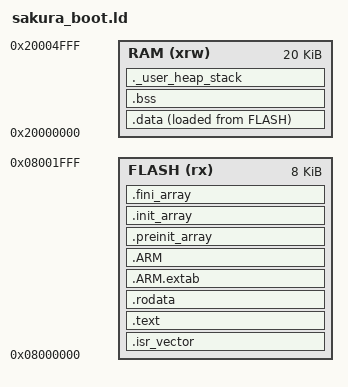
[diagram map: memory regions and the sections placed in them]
/*
 * Linker script for sakura_boot CAN bootloader
 * STM32F103CBTx (FCM32 clone) — 128KB FLASH, 20KB RAM
 *
 * Memory map:
 *   0x08000000 - 0x08001FFF  Bootloader (8KB)
 *   0x08002000 - 0x080023FF  Metadata page (1KB)  — written by host during flash
 *   0x08002400 - 0x0800FBFF  Application (54KB)
 *   0x0800FC00 - 0x0800FFFF  NVS (1KB)
 */

ENTRY(Reset_Handler)

MEMORY
{
  RAM (xrw)    : ORIGIN = 0x20000000, LENGTH = 20K
  FLASH (rx)   : ORIGIN = 0x08000000, LENGTH = 8K
}

_estack = ORIGIN(RAM) + LENGTH(RAM);
_Min_Stack_Size = 0x200;

SECTIONS
{
  .isr_vector :
  {
    . = ALIGN(4);
    KEEP(*(.isr_vector))
    . = ALIGN(4);
  } >FLASH

  .text :
  {
    . = ALIGN(4);
    *(.text)
    *(.text*)
    *(.glue_7)
    *(.glue_7t)
    *(.eh_frame)
    KEEP (*(.init))
    KEEP (*(.fini))
    . = ALIGN(4);
    _etext = .;
  } >FLASH

  .rodata :
  {
    . = ALIGN(4);
    *(.rodata)
    *(.rodata*)
    . = ALIGN(4);
  } >FLASH

  .ARM.extab (READONLY) :
  {
    *(.ARM.extab* .gnu.linkonce.armextab.*)
  } >FLASH

  .ARM (READONLY) :
  {
    __exidx_start = .;
    *(.ARM.exidx*)
    __exidx_end = .;
  } >FLASH

  .preinit_array (READONLY) :
  {
    . = ALIGN(4);
    PROVIDE_HIDDEN (__preinit_array_start = .);
    KEEP (*(.preinit_array*))
    PROVIDE_HIDDEN (__preinit_array_end = .);
    . = ALIGN(4);
  } >FLASH

  .init_array (READONLY) :
  {
    . = ALIGN(4);
    PROVIDE_HIDDEN (__init_array_start = .);
    KEEP (*(SORT(.init_array.*)))
    KEEP (*(.init_array*))
    PROVIDE_HIDDEN (__init_array_end = .);
    . = ALIGN(4);
  } >FLASH

  .fini_array (READONLY) :
  {
    . = ALIGN(4);
    PROVIDE_HIDDEN (__fini_array_start = .);
    KEEP (*(SORT(.fini_array.*)))
    KEEP (*(.fini_array*))
    PROVIDE_HIDDEN (__fini_array_end = .);
    . = ALIGN(4);
  } >FLASH

  .data :
  {
    . = ALIGN(4);
    _sdata = .;
    *(.data)
    *(.data*)
    *(.RamFunc)
    *(.RamFunc*)
    . = ALIGN(4);
    _edata = .;
  } >RAM AT> FLASH

  _sidata = LOADADDR(.data);

  .bss (NOLOAD) :
  {
    . = ALIGN(4);
    _sbss = .;
    __bss_start__ = _sbss;
    *(.bss)
    *(.bss*)
    *(COMMON)
    . = ALIGN(4);
    _ebss = .;
    __bss_end__ = _ebss;
  } >RAM

  ._user_heap_stack (NOLOAD) :
  {
    . = ALIGN(8);
    PROVIDE ( end = . );
    PROVIDE ( _end = . );
    . = . + _Min_Stack_Size;
    . = ALIGN(8);
  } >RAM

  /DISCARD/ :
  {
    *(.ARM.attributes)
  }
}
